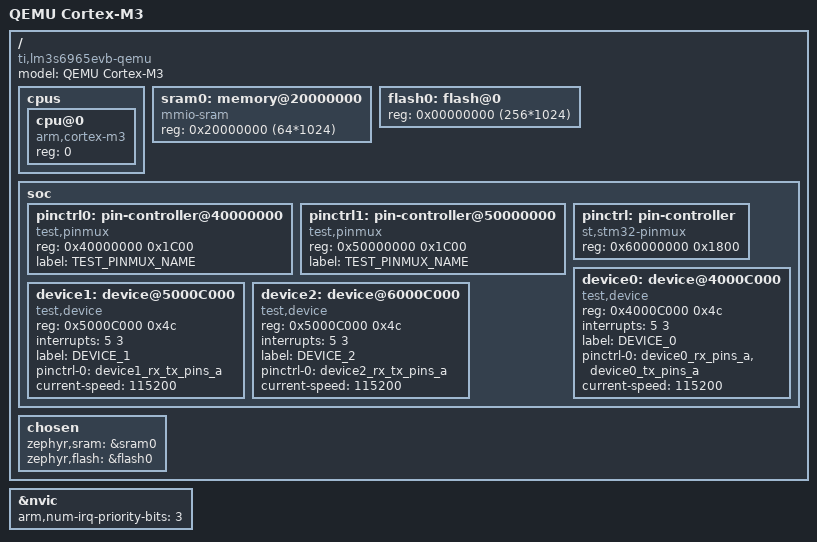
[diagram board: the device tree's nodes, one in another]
/dts-v1/;

#include <arm/armv7-m.dtsi>
#include "test-pinctrl.dtsi"

/ {
	cpus {
		#address-cells = <1>;
		#size-cells = <0>;

		cpu@0 {
			device_type = "cpu";
			compatible = "arm,cortex-m3";
			reg = <0>;
		};
	};

	sram0: memory@20000000 {
		device_type = "memory";
		compatible = "mmio-sram";
		reg = <0x20000000 (64*1024)>;
	};

	flash0: flash@0 {
		reg = <0x00000000 (256*1024)>;
	};

	soc {
		pinctrl0: pin-controller@40000000 {
			compatible = "test,pinmux";
			#address-cells = <1>;
			#size-cells = <1>;
			reg = <0x40000000 0x1C00>;
                        label = TEST_PINMUX_NAME;
                        status = "ok";
		};

		pinctrl1: pin-controller@50000000 {
			compatible = "test,pinmux";
			#address-cells = <1>;
			#size-cells = <1>;
			reg = <0x50000000 0x1C00>;
                        label = TEST_PINMUX_NAME;
                        status = "ok";
		};

		pinctrl: pin-controller {
			compatible = "st,stm32-pinmux";
			#address-cells = <1>;
			#size-cells = <1>;
			reg = <0x60000000 0x1800>;
                        status = "ok";
		};

		device0: device@4000C000 {
			compatible = "test,device";
			reg = <0x4000C000 0x4c>;
			interrupts = <5 3>;
			status = "disabled";
			label = "DEVICE_0";
		};

		device1: device@5000C000 {
			compatible = "test,device";
			reg = <0x5000C000 0x4c>;
			interrupts = <5 3>;
			status = "disabled";
			label = "DEVICE_1";
		};

		device2: device@6000C000 {
			compatible = "test,device";
			reg = <0x5000C000 0x4c>;
			interrupts = <5 3>;
			status = "disabled";
			label = "DEVICE_2";
		};

	};
};

&nvic {
	arm,num-irq-priority-bits = <3>;
};

/ {
	model = "QEMU Cortex-M3";
	compatible = "ti,lm3s6965evb-qemu", "ti,lm3s6965";

	chosen {
		zephyr,sram = &sram0;
		zephyr,flash = &flash0;
	};
};

&device0 {
        pinctrl-0 = <&device0_rx_pins_a &device0_tx_pins_a>;
        pinctrl-names = "default";
	status = "ok";
	current-speed = <115200>;
};

&device1 {
        pinctrl-0 = <&device1_rx_tx_pins_a>;
        pinctrl-names = "default";
	status = "ok";
	current-speed = <115200>;
};

&device2 {
        pinctrl-0 = <&device2_rx_tx_pins_a>;
        pinctrl-names = "default";
	status = "ok";
	current-speed = <115200>;
};
